# AM13E23219 register map
Vendor: Texas Instruments; File version: 1.0
CPU: CM33 r0p1, little endian, MPU, FPU, VTOR, 4 interrupt priority bits
Registers are 32-bit, read-write, reset 0x0 unless marked. A register's access mark holds for its fields unless they carry their own. Offsets are from the block's base; [hi:lo] are bit positions; {n}, {i} and the like mark numbered series; 'fields as' and 'values as' point back to an identical list; <NAME> marks a mode.

## SYSCTL (part 1 of 2) — SYSCTL module
Base 0x400AF000
0x1020 IIDX ro — SYSCTL interrupt index
  [2:0] STAT — The SYSCTL interrupt index (IIDX) register generates a value corresponding to the highest priority pending interrupt source. This value may be used as an address offset for fast, deterministic handling in the interrupt service routine. A read of the IIDX register will clear the corresponding interrupt status in the RIS and MIS registers.
    0=NO_INTR (No interrupt pending); 1=LFOSCGOOD (LFOSCGOOD interrupt pending); 2=ANACLKERR; 3=FLASHSEC; 4=SRAMSEC; 5=HFCLKGOOD; 6=SYSPLLGOOD; 7=HSCLKGOOD
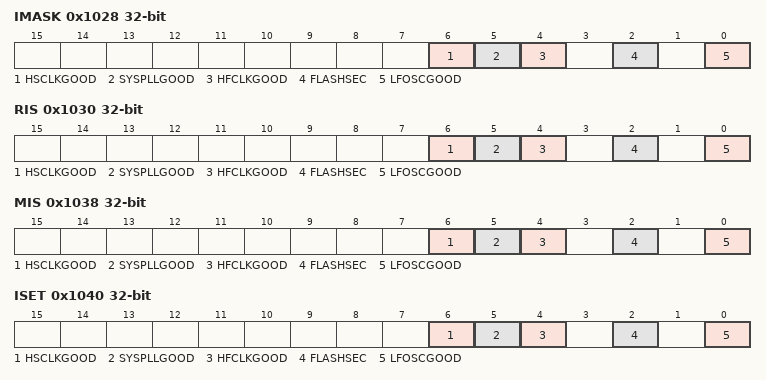
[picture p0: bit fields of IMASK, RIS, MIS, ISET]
0x1028 IMASK — SYSCTL interrupt mask
  [6] HSCLKGOOD
    0=DISABLE; 1=ENABLE
  [5] SYSPLLGOOD
    0=DISABLE; 1=ENABLE
  [4] HFCLKGOOD
    0=DISABLE; 1=ENABLE
  [2] FLASHSEC — Flash Single Error Correct
    0=DISABLE; 1=ENABLE
  [0] LFOSCGOOD — Enable or disable the LFOSCGOOD interrupt. LFOSCGOOD indicates that the LFOSC has started successfully.
    0=DISABLE (Interrupt disabled); 1=ENABLE (Interrupt enabled)
0x1030 RIS ro — SYSCTL raw interrupt status
  [6] HSCLKGOOD
    0=FALSE; 1=TRUE
  [5] SYSPLLGOOD
    0=FALSE; 1=TRUE
  [4] HFCLKGOOD
    0=FALSE; 1=TRUE
  [2] FLASHSEC — Flash Single Error Correct
    0=FALSE; 1=TRUE
  [0] LFOSCGOOD — Raw status of the LFOSCGOOD interrupt.
    0=FALSE (No interrupt pending); 1=TRUE (Interrupt pending)
0x1038 MIS ro — SYSCTL masked interrupt status
  [6] HSCLKGOOD
    0=FALSE; 1=TRUE
  [5] SYSPLLGOOD
    0=FALSE; 1=TRUE
  [4] HFCLKGOOD
    0=FALSE; 1=TRUE
  [2] FLASHSEC — Flash Single Error Correct
    0=FALSE; 1=TRUE
  [0] LFOSCGOOD — Masked status of the LFOSCGOOD interrupt.
    0=FALSE (No interrupt pending); 1=TRUE (Interrupt pending)
0x1040 ISET — SYSCTL interrupt set
  [6] HSCLKGOOD
    0=NO_EFFECT; 1=SET
  [5] SYSPLLGOOD
    0=NO_EFFECT; 1=SET
  [4] HFCLKGOOD
    0=NO_EFFECT; 1=SET
  [2] FLASHSEC — Flash Single Error Correct
    0=NO_EFFECT; 1=SET
  [0] LFOSCGOOD — Set the LFOSCGOOD interrupt.
    0=NO_EFFECT (Writing 0h has no effect); 1=SET (Set interrupt)
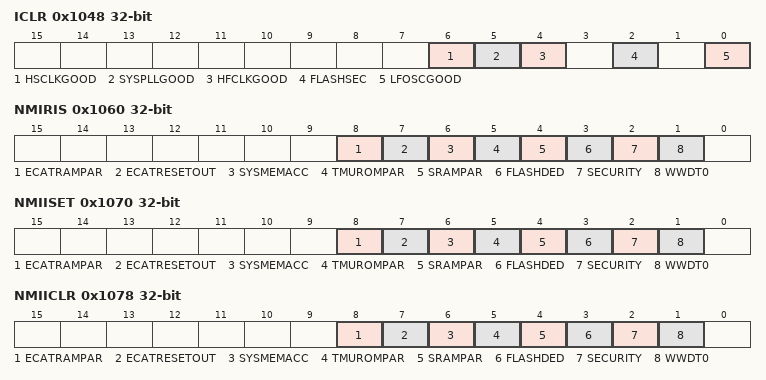
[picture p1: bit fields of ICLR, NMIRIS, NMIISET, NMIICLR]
0x1048 ICLR — SYSCTL interrupt clear
  [6] HSCLKGOOD
    0=NO_EFFECT; 1=CLR
  [5] SYSPLLGOOD
    0=NO_EFFECT; 1=CLR
  [4] HFCLKGOOD
    0=NO_EFFECT; 1=CLR
  [2] FLASHSEC — Flash Single Error Correct
    0=NO_EFFECT; 1=CLR
  [0] LFOSCGOOD — Clear the LFOSCGOOD interrupt.
    0=NO_EFFECT (Writing 0h has no effect); 1=CLR (Clear interrupt)
0x1050 NMIIIDX ro — NMI interrupt index
  [3:0] STAT — The NMI interrupt index (NMIIIDX) register generates a value corresponding to the highest priority pending NMI source. This value may be used as an address offset for fast, deterministic handling in the NMI service routine. A read of the NMIIIDX register will clear the corresponding interrupt status in the NMIRIS register.
    0=NO_INTR (No NMI pending); 1=BORLVL (Reserved); 2=WWDT0; 3=SECURITY; 4=FLASHDED; 5=SRAMPAR; 6=TMUROMPAR; 7=SYSMEMACC; 8=ECATRESETOUT; 9=ECATRAMPAR
0x1060 NMIRIS ro — NMI raw interrupt status
  [all] fields
    0=FALSE; 1=TRUE
  [8] ECATRAMPAR — ECATSS RAM Parity error
  [7] ECATRESETOUT — ECATSS RESET out
  [6] SYSMEMACC — SYSMEM Access error
  [5] TMUROMPAR — TMU ROM Parity error
  [4] SRAMPAR — SRAM Parity Error Detect
  [3] FLASHDED — Flash Double Error Detect
  [2] SECURITY — Security Fault
  [1] WWDT0 — Watch Dog 0 Fault
0x1070 NMIISET — NMI interrupt set
  [all] fields
    0=NO_EFFECT; 1=SET
  [8] ECATRAMPAR — ECATSS RAM Parity error
  [7] ECATRESETOUT — ECATSS RESET out
  [6] SYSMEMACC — SYSMEM Access error
  [5] TMUROMPAR — TMU ROM Parity error
  [4] SRAMPAR — SRAM Parity Error Detect
  [3] FLASHDED — Flash Double Error Detect
  [2] SECURITY — Security Fault
  [1] WWDT0 — Watch Dog 0 Fault
0x1078 NMIICLR — NMI interrupt clear
  [all] fields
    0=NO_EFFECT; 1=CLR
  [8] ECATRAMPAR — ECATSS RAM Parity error
  [7] ECATRESETOUT — ECATSS RESET out
  [6] SYSMEMACC — SYSMEM Access error
  [5] TMUROMPAR — TMU ROM Parity error
  [4] SRAMPAR — SRAM Parity Error Detect
  [3] FLASHDED — Flash Double Error Detect
  [2] SECURITY — Security Fault
  [1] WWDT0 — Watch Dog 0 Fault
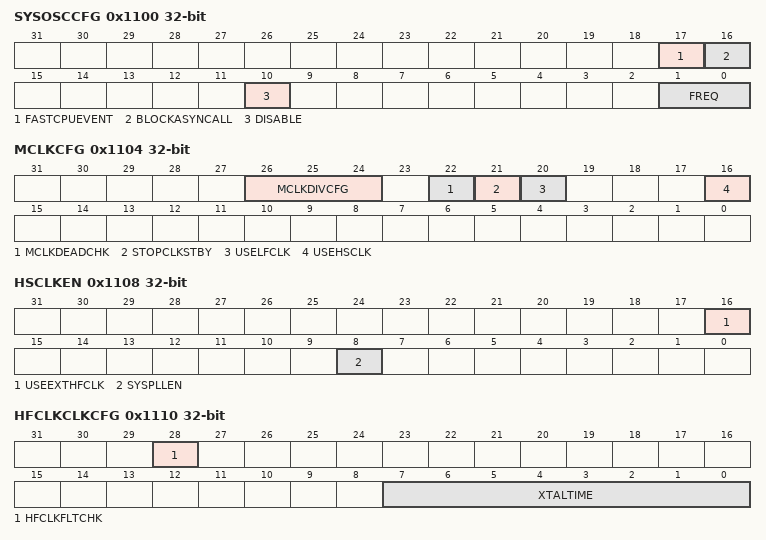
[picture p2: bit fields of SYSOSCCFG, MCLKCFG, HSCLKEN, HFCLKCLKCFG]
0x1100 SYSOSCCFG access per field — SYSOSC configuration
  [17] FASTCPUEVENT rw — if disabled CPU will not wakeup and continue in STANDBY
    0=DISABLE (An interrupt to the CPU will not assert a fast clock request); 1=ENABLE (An interrupt to the CPU will assert a fast clock request)
  [16] BLOCKASYNCALL rw — BLOCKASYNCALL may be used to mask block all asynchronous fast clock requests, preventing hardware from dynamically changing the active clock configuration when operating in a given mode.
    0=DISABLE (Asynchronous fast clock requests are controlled by the requesting peripheral); 1=ENABLE (All asynchronous fast clock requests are blocked)
  [10] DISABLE ro — DISABLE sets the SYSOSC enable/disable policy. SYSOSC may be powered off in RUN, SLEEP, and STOP modes to reduce power consumption. When SYSOSC is disabled, MCLK and ULPCLK are sourced from LFCLK.
    0=DISABLE (Do not disable SYSOSC); 1=ENABLE (Disable SYSOSC immediately and source MCLK and ULPCLK from LFCLK)
  [1:0] FREQ rw — Target operating frequency for the system oscillator (SYSOSC)
    0=SYSOSCBASE (Base frequency (32MHz)); 1=SYSOSC4M (Low frequency (4MHz))
0x1104 MCLKCFG access per field — Main clock (MCLK) configuration
  [26:24] MCLKDIVCFG rw — MCLK Divider Configuration bits [1:0] are defined as MCLK4 is Bypass, MCLK2 is Bypass
    0=RATIO_1_1_1 (MCLK: No Divide, MCLK2: No Divide, MCLK4: No Divide); 1=RATIO_1_1_2 (MCLK: No Divide, MCLK2: No Divide, MCLK4: Divide MCLK by 2); 3=RATIO_1_1_4 (MCLK: No Divide, MCLK2: No Divide, MCLK4: Divide MCLK by 4); 5=RATIO_1_2_2 (MCLK: No Divide, MCLK2: Divide MCLK by 2, MCLK4: Divide MCLK by 2); 7=RATIO_1_2_4 (MCLK: No Divide, MCLK2: Divide MCLK by 2, MCLK4: MCLK by 4)
  [22] MCLKDEADCHK rw — MCLKDEADCHK enables or disables the continuous MCLK dead check monitor. LFCLK must be running before MCLKDEADCHK is enabled.
    0=DISABLE (The MCLK dead check monitor is disabled); 1=ENABLE (The MCLK dead check monitor is enabled)
  [21] STOPCLKSTBY rw — STOPCLKSTBY sets the STANDBY mode policy (STANDBY0 or STANDBY1). When set, ULPCLK and LFCLK are disabled to all peripherals in STANDBY mode, with the exception of TIMG0 and TIMG1 which continue to run. Wake-up is only possible via an asynchronous fast clock request.
    0=DISABLE (ULPCLK/LFCLK runs to all PD0 peripherals in STANDBY mode); 1=ENABLE (ULPCLK/LFCLK is disabled to all peripherals in STANDBY mode except TIMG0 and TIMG1)
  [20] USELFCLK ro — LFCLK is not an MCLK sourcei in PD1, tied 0.
    0=DISABLE (MCLK will not use the low frequency clock (LFCLK)); 1=ENABLE (MCLK will use the low frequency clock (LFCLK))
  [16] USEHSCLK rw — USEHSCLK, together with USELFCLK, sets the MCLK source policy. Set USEHSCLK to use HSCLK (HFCLK or SYSPLL) as the MCLK source in RUN and SLEEP modes.
    0=DISABLE (MCLK will not use the high speed clock (HSCLK)); 1=ENABLE (MCLK will use the high speed clock (HSCLK) in RUN and SLEEP mode)
0x1108 HSCLKEN — High-speed clock (HSCLK) source enable/disable
  [16] USEEXTHFCLK — USEEXTHFCLK selects the HFCLK_IN digital clock input to be the source for HFCLK.
    0=DISABLE (Use XTAL as the HFCLK source); 1=ENABLE (Use the HFCLK_IN digital clock input as the HFCLK source)
  [8] SYSPLLEN — SYSPLLEN enables or disables the system phase-lock loop (SYSPLL).
    0=DISABLE (Disable the SYSPLL); 1=ENABLE (Enable the SYSPLL)
0x110C HSCLKCFG — High-speed clock (HSCLK) source selection
  [0] HSCLKSEL — HSCLKSEL selects the HSCLK source (SYSPLL or HFCLK).
    0=SYSPLL (HSCLK is sourced from the SYSPLL); 1=HFCLKCLK (HSCLK is sourced from the HFCLK)
0x1110 HFCLKCLKCFG — High-frequency clock (HFCLK) configuration
  [28] HFCLKFLTCHK — HFCLKFLTCHK enables or disables the HFCLK startup monitor.
    0=DISABLE (HFCLK startup is not checked); 1=ENABLE (HFCLK startup is checked)
  [7:0] XTALTIME — XTALTIME specifies the XTAL startup time in 64us resolution. If the HFCLK startup monitor is enabled (HFCLKFLTCHK), XTAL will be checked after this time expires.
    0=MINSTARTTIME (Minimum startup time (approximatly zero)); 255=MAXSTARTTIME (Maximum startup time (approximatly 16.32ms))
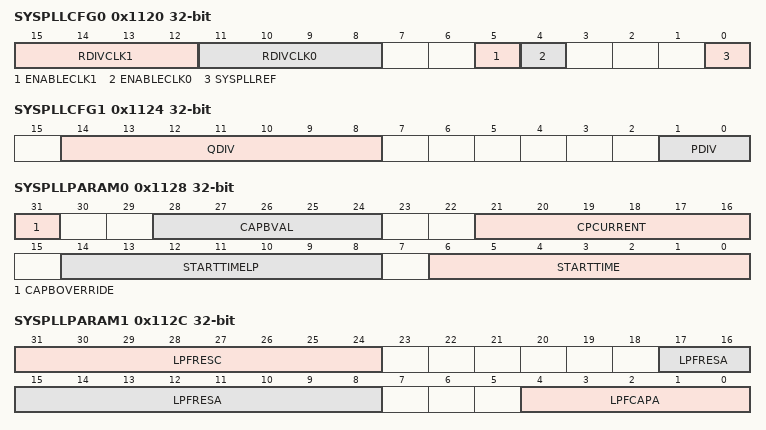
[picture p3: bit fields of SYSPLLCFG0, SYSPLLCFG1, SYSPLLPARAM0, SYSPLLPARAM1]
0x1120 SYSPLLCFG0 — SYSPLL reference and output configuration
  [15:12] RDIVCLK1 — RDIVCLK1 sets the final divider for the SYSPLLCLK1 output.
    0=CLK1DIV2 (SYSPLLCLK1 is divided by 2); 1=CLK1DIV4 (SYSPLLCLK1 is divided by 4); 2=CLK1DIV6 (SYSPLLCLK1 is divided by 6); 3=CLK1DIV8 (SYSPLLCLK1 is divided by 8); 4=CLK1DIV10 (SYSPLLCLK1 is divided by 10); 5=CLK1DIV12 (SYSPLLCLK1 is divided by 12); 6=CLK1DIV14 (SYSPLLCLK1 is divided by 14); 7=CLK1DIV16 (SYSPLLCLK1 is divided by 16); 8=CLK1DIV18 (SYSPLLCLK1 is divided by 18); 9=CLK1DIV20 (SYSPLLCLK1 is divided by 20); 10=CLK1DIV22 (SYSPLLCLK1 is divided by 22); 11=CLK1DIV24 (SYSPLLCLK1 is divided by 24); 12=CLK1DIV26 (SYSPLLCLK1 is divided by 26); 13=CLK1DIV28 (SYSPLLCLK1 is divided by 28); 14=CLK1DIV30 (SYSPLLCLK1 is divided by 30); 15=CLK1DIV32 (SYSPLLCLK1 is divided by 32)
  [11:8] RDIVCLK0 — RDIVCLK0 sets the final divider for the SYSPLLCLK0 output.
    0=CLK0DIV2 (SYSPLLCLK0 is divided by 2); 1=CLK0DIV4 (SYSPLLCLK0 is divided by 4); 2=CLK0DIV6 (SYSPLLCLK0 is divided by 6); 3=CLK0DIV8 (SYSPLLCLK0 is divided by 8); 4=CLK0DIV10 (SYSPLLCLK0 is divided by 10); 5=CLK0DIV12 (SYSPLLCLK0 is divided by 12); 6=CLK0DIV14 (SYSPLLCLK0 is divided by 14); 7=CLK0DIV16 (SYSPLLCLK0 is divided by 16); 8=CLK0DIV18 (SYSPLLCLK0 is divided by 18); 9=CLK0DIV20 (SYSPLLCLK0 is divided by 20); 10=CLK0DIV22 (SYSPLLCLK0 is divided by 22); 11=CLK0DIV24 (SYSPLLCLK0 is divided by 24); 12=CLK0DIV26 (SYSPLLCLK0 is divided by 26); 13=CLK0DIV28 (SYSPLLCLK0 is divided by 28); 14=CLK0DIV30 (SYSPLLCLK0 is divided by 30); 15=CLK0DIV32 (SYSPLLCLK0 is divided by 32)
  [5] ENABLECLK1 — ENABLECLK1 enables or disables the SYSPLLCLK1 output.
    0=DISABLE (SYSPLLCLK1 is disabled); 1=ENABLE (SYSPLLCLK1 is enabled)
  [4] ENABLECLK0 — ENABLECLK0 enables or disables the SYSPLLCLK0 output.
    0=DISABLE (SYSPLLCLK0 is disabled); 1=ENABLE (SYSPLLCLK0 is enabled)
  [0] SYSPLLREF — SYSPLLREF selects the system PLL (SYSPLL) reference clock source.
    0=SYSOSC (SYSPLL reference is SYSOSC); 1=HFCLK (SYSPLL reference is HFCLK)
0x1124 SYSPLLCFG1 — SYSPLL reference and feedback divider
  [14:8] QDIV — QDIV selects the SYSPLL feedback path divider.
    0=INVALID (Divide-by-one is not a valid QDIV option); 1=QDIVMIN (Feedback path is divided by 2); 126=QDIVMAX (Feedback path is divided by 127 (0x7E))
  [1:0] PDIV — PDIV selects the SYSPLL reference clock prescale divider.
    0=REFDIV1 (SYSPLLREF is not divided); 1=REFDIV2 (SYSPLLREF is divided by 2); 2=REFDIV4 (SYSPLLREF is divided by 4); 3=REFDIV8 (SYSPLLREF is divided by 8)
0x1128 SYSPLLPARAM0 — SYSPLL PARAM0 (load from FACTORY region)
  [31] CAPBOVERRIDE — CAPBOVERRIDE controls the override for Cap B
    0=DISABLE (Cap B override disabled); 1=ENABLE (Cap B override enabled)
  [28:24] CAPBVAL — Override value for Cap B
  [21:16] CPCURRENT — Charge pump current
  [14:8] STARTTIMELP — Startup time from low power mode exit to locked clock, in 1us resolution
  [6:0] STARTTIME — Startup time from enable to locked clock, in 1us resolution
0x112C SYSPLLPARAM1 — SYSPLL PARAM1 (load from FACTORY region)
  [31:24] LPFRESC — Loop filter Res C
  [17:8] LPFRESA — Loop filter Res A
  [4:0] LPFCAPA — Loop filter Cap A
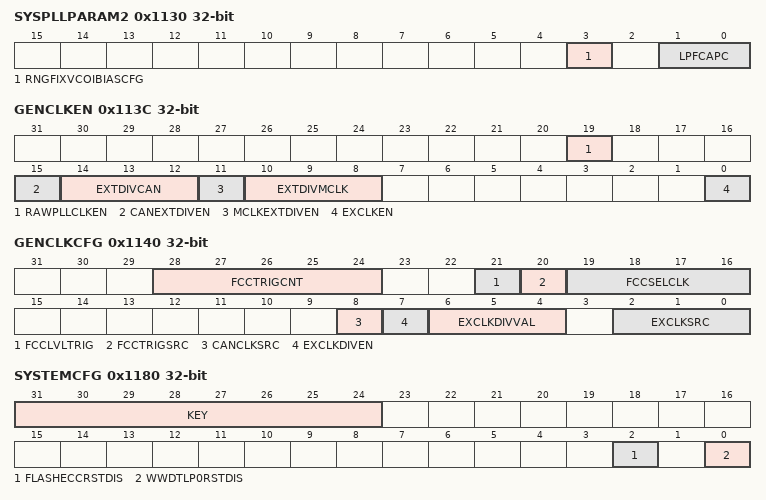
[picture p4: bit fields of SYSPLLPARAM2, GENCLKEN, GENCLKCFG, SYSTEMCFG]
0x1130 SYSPLLPARAM2 — SYSPLL PARAM2 (load from FACTORY region)
  [3] RNGFIXVCOIBIASCFG — 0 value for Temperature Compensation R addition
  [1:0] LPFCAPC — Loop filter Cap C
0x1134 SYSPLLLDOCTL — SYSPLL LDO CTL (load from FACTORY region)
  [15:0] LDOCTLLOWV — LDO Configurability
0x1138 SYSPLLLDOPROG — SYSPLL LDO VOUT PROG (load from FACTORY region)
  [2:0] LDOVOUTPROGLOWV — HPLL LDO Vout Prog
0x113C GENCLKEN — General clock enable control
  [19] RAWPLLCLKEN — RAWPLLCLKEN enables or disables the 400MHz RAW PLL clock into the system
    0=DISBLE (400MHz RAW PLL clock is disabled); 1=ENABLE (400MHz RAW PLL clock is enabled)
  [15] CANEXTDIVEN — CANEXTDIVEN enables or disables the divider function of the PLL Source to CAN.
    0=PASSTHRU (CLock divider is disabled (passthrough, EXTDIVCAN is not applied)); 1=ENABLE (Clock divider is enabled (EXTDIVCAN is applied))
  [14:12] EXTDIVCAN — EXTDIVCAN selects the divider value for the divider for the PLL Source to CAN.
    0=DIV2 (CLK_OUT source is divided by 2); 1=DIV4 (CLK_OUT source is divided by 4); 2=DIV6 (CLK_OUT source is divided by 6); 3=DIV8 (CLK_OUT source is divided by 8); 4=DIV10 (CLK_OUT source is divided by 10); 5=DIV12 (CLK_OUT source is divided by 12); 6=DIV14 (CLK_OUT source is divided by 14); 7=DIV16 (CLK_OUT source is divided by 16)
  [11] MCLKEXTDIVEN — MCLKEXTDIVEN enables or disables the divider function of the PLL Source to MCLK.
    0=PASSTHRU (CLock divider is disabled (passthrough, EXTDIVMCLK is not applied)); 1=ENABLE (Clock divider is enabled (EXTDIVMCLK is applied))
  [10:8] EXTDIVMCLK — EXTDIVMCLK selects the divider value for the divider for the PLL Source MCLK.
    values as EXTDIVCAN
  [0] EXCLKEN — EXCLKEN enables the CLK_OUT external clock output block.
    0=DISABLE (CLK_OUT block is disabled); 1=ENABLE (CLK_OUT block is enabled)
0x1140 GENCLKCFG — General clock configuration
  [28:24] FCCTRIGCNT — FCCTRIGCNT specifies the number of trigger clock periods in the trigger window. FCCTRIGCNT=0h (one trigger clock period) up to 1Fh (32 trigger clock periods) may be specified.
  [21] FCCLVLTRIG — FCCLVLTRIG selects the frequency clock counter (FCC) trigger mode.
    0=RISE2RISE (Rising edge to rising edge triggered); 1=LEVEL (Level triggered)
  [20] FCCTRIGSRC — FCCTRIGSRC selects the frequency clock counter (FCC) trigger source.
    0=EXTPIN (FCC trigger is the external pin); 1=LFCLK (FCC trigger is the LFCLK)
  [19:16] FCCSELCLK — FCCSELCLK selectes the frequency clock counter (FCC) clock source.
    0=MCLKBY4 (FCC clock is MCLK/4); 1=SYSOSC (FCC clock is SYSOSC); 2=HFCLK (FCC clock is HFCLK); 3=EXTCLK (FCC clock is the CLK_OUT selection); 4=SYSPLLCLK0 (FCC clock is SYSPLLCLK0); 5=SYSPLLCLK1 (FCC clock is SYSPLLCLK1); 6=ECAT25CLK (FCC clock is ECAT25CLK); 7=FCCIN (FCC clock is the FCCIN external input)
  [8] CANCLKSRC — CANCLKSRC selects the CANCLK source.
    0=HFCLK (CANCLK source is HFCLK); 1=SYSPLLOUT (CANCLK source is SYSPLLCLK)
  [7] EXCLKDIVEN — EXCLKDIVEN enables or disables the divider function of the CLK_OUT external clock output block.
    0=PASSTHRU (CLock divider is disabled (passthrough, EXCLKDIVVAL is not applied)); 1=ENABLE (Clock divider is enabled (EXCLKDIVVAL is applied))
  [6:4] EXCLKDIVVAL — EXCLKDIVVAL selects the divider value for the divider in the CLK_OUT external clock output block.
    values as GENCLKEN.EXTDIVCAN
  [2:0] EXCLKSRC — EXCLKSRC selects the source for the CLK_OUT external clock output block. ULPCLK and MFPCLK require the CLK_OUT divider (EXCLKDIVEN) to be enabled
    0=SYSOSC (CLK_OUT is SYSOSC); 1=ULPCLK (CLK_OUT is ULPCLK (EXCLKDIVEN must be enabled)); 2=LFCLK (CLK_OUT is LFCLK); 3=MFPCLK (CLK_OUT is MFPCLK (EXCLKDIVEN must be enabled)); 4=HFCLK (CLK_OUT is HFCLK); 5=SYSPLLOUT1 (CLK_OUT is SYSPLLCLK1 (SYSPLLCLK1 must be <=48MHz))
0x1144 PMODECFG — Power mode configuration
  [1:0] DSLEEP — DSLEEP selects the operating mode to enter upon a DEEPSLEEP request from the CPU.
    0=STOP (STOP mode is entered); 1=STANDBY (STANDBY mode is entered); 2=SHUTDOWN (SHUTDOWN mode is entered)
0x1148 MLDOLPENCFG — LDO Configuration Control
  [0] CVLODIS — Control to disable lowering the core voltage for STOP and STANDBY
    0=FALSE (Lower Core Voltage for STOP and STANDBY mode); 1=TRUE (Do Not Lower Core Voltage for STOP and STANDBY mode to provide faster wakeup)
0x1150 FCC ro — Frequency clock counter (FCC) count
  [21:0] DATA — Frequency clock counter (FCC) count value.
0x1154 PMULDOSPARECTL access not given — LDO Spare Control
0x1158 SYSCTL_ECO_REG1 access not given
0x115C SYSCTL_ECO_REG2 access not given
0x1180 SYSTEMCFG access per field — System configuration
  [31:24] KEY wo — Key which must be written for the write to take effect.
    27=KEY (Write key.)
  [2] FLASHECCRSTDIS rw — FLASHECCRSTDIS specifies whether a flash ECC double error detect (DED) will trigger a SYSRST or an NMI.
    0=FALSE (Flash ECC DED will trigger a SYSRST); 1=TRUE (Flash ECC DED will trigger a NMI)
  [0] WWDTLP0RSTDIS rw — WWDTLP0RSTDIS specifies whether a WWDT Error Event will trigger a BOOTRST or an NMI.
    0=FALSE (WWDTLP0 Error Event will trigger a BOOTRST); 1=TRUE (WWDTLP0 Error Event will trigger an NMI)
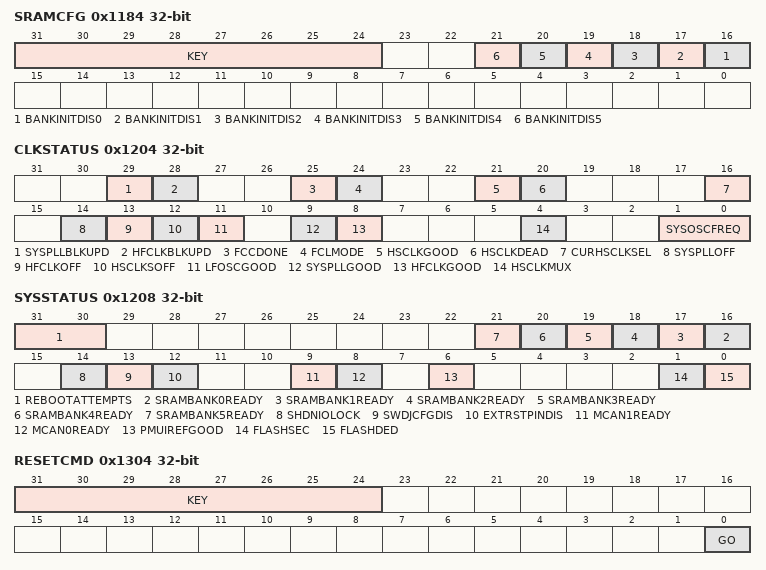
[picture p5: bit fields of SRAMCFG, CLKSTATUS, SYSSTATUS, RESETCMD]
0x1184 SRAMCFG access per field — System SRAM configuration
  [31:24] KEY wo — Key which must be written for the write to take effect.
    181=KEY (Write key.)
  [n+16] BANKINITDIS{n} rw (n=0..5) — SRAM BANK{n} Initialization
    0=FALSE (SRAM BANK{n} will Initialize when transitioning from OFF to ON); 1=TRUE (SRAM BANK{n} will NOT Initialize when transitioning from OFF to ON)
0x1200 WRITELOCK — SYSCTL register write lockout
  [0] ACTIVE — ACTIVE controls whether critical SYSCTL registers are write protected or not.
    0=DISABLE (Allow writes to lockable registers); 1=ENABLE (Disallow writes to lockable registers)
0x1204 CLKSTATUS ro — Clock module (CKM) status
  [29] SYSPLLBLKUPD — SYSPLLBLKUPD indicates when writes to SYSPLLCFG0/1 and SYSPLLPARAM0/1 are blocked.
    0=FALSE (writes to SYSPLLCFG0/1 and SYSPLLPARAM0/1 are allowed); 1=TRUE (writes to SYSPLLCFG0/1 and SYSPLLPARAM0/1 are blocked)
  [28] HFCLKBLKUPD — HFCLKBLKUPD indicates when writes to the HFCLKCLKCFG register are blocked.
    0=FALSE (Writes to HFCLKCLKCFG are allowed); 1=TRUE (Writes to HFCLKCLKCFG are blocked)
  [25] FCCDONE — FCCDONE indicates when a frequency clock counter capture is complete.
    0=NOTDONE (FCC capture is not done); 1=DONE (FCC capture is done)
  [24] FCLMODE — FCLMODE indicates if the SYSOSC frequency correction loop (FCL) is enabled.
    0=DISABLED (SYSOSC FCL is disabled); 1=ENABLED (SYSOSC FCL is enabled)
  [21] HSCLKGOOD — HSCLKGOOD is set by hardware if the selected clock source for HSCLK started successfully.
    0=FALSE (The HSCLK source did not start correctly); 1=TRUE (The HSCLK source started correctly)
  [20] HSCLKDEAD — HSCLKDEAD is set by hardware if the selected source for HSCLK was started but did not start successfully.
    0=FALSE (The HSCLK source was not started or started correctly); 1=TRUE (The HSCLK source did not start correctly)
  [16] CURHSCLKSEL — CURHSCLKSEL indicates the current clock source for HSCLK.
    0=SYSPLL (HSCLK is currently sourced from the SYSPLL); 1=HFCLK (HSCLK is currently sourced from the HFCLK)
  [14] SYSPLLOFF — SYSPLLOFF indicates if the SYSPLL is disabled or was dead at startup. When the SYSPLL is started, SYSPLLOFF is cleared by hardware. Following startup of the SYSPLL, if the SYSPLL startup monitor determines that the SYSPLL was not started correctly, SYSPLLOFF is set.
    0=FALSE (SYSPLL started correctly and is enabled); 1=TRUE (SYSPLL is disabled or was dead startup)
  [13] HFCLKOFF — HFCLKOFF indicates if the HFCLK is disabled or was dead at startup. When the HFCLK is started, HFCLKOFF is cleared by hardware. Following startup of the HFCLK, if the HFCLK startup monitor determines that the HFCLK was not started correctly, HFCLKOFF is set.
    0=FALSE (HFCLK started correctly and is enabled); 1=TRUE (HFCLK is disabled or was dead at startup)
  [12] HSCLKSOFF — HSCLKSOFF is set when the high speed clock sources (SYSPLL, HFCLK) are disabled or dead. It is the logical AND of HFCLKOFF and SYSPLLOFF.
    0=FALSE (SYSPLL, HFCLK, or both were started correctly and remain enabled); 1=TRUE (SYSPLL and HFCLK are both either off or dead)
  [11] LFOSCGOOD — LFOSCGOOD indicates when the LFOSC startup has completed and the LFOSC is ready for use.
    0=FALSE (LFOSC is not ready); 1=TRUE (LFOSC is ready)
  [9] SYSPLLGOOD — SYSPLLGOOD indicates if the SYSPLL started correctly. When the SYSPLL is started, SYSPLLGOOD is cleared by hardware. After the startup settling time has expired, the SYSPLL status is tested. If the SYSPLL started successfully the SYSPLLGOOD bit is set, else it is left cleared.
    0=FALSE (SYSPLL did not start correctly); 1=TRUE (SYSPLL started correctly)
  [8] HFCLKGOOD — HFCLKGOOD indicates that the HFCLK started correctly. When the XTAL is started or HFCLK_IN is selected as the HFCLK source, this bit will be set by hardware if a valid HFCLK is detected, and cleared if HFCLK is not operating within the expected range.
    0=FALSE (HFCLK did not start correctly); 1=TRUE (HFCLK started correctly)
  [4] HSCLKMUX — HSCLKMUX indicates if MCLK is currently sourced from the high-speed clock (HSCLK).
    0=SYSOSC (MCLK is not sourced from HSCLK); 1=HSCLK (MCLK is sourced from HSCLK)
  [1:0] SYSOSCFREQ — SYSOSCFREQ indicates the current SYSOSC operating frequency.
    0=SYSOSC32M (SYSOSC is at base frequency (32MHz)); 1=SYSOSC4M (SYSOSC is at low frequency (4MHz))
0x1208 SYSSTATUS ro — System status information
  [31:30] REBOOTATTEMPTS — REBOOTATTEMPTS indicates the number of boot attempts taken before the user application starts.
  [n+16] SRAMBANK{n}READY (n=0..5) — SRAM BANK{n} READY STATE
    0=FALSE (SRAM BANK{n} is NOT READY for access); 1=TRUE (SRAM BANK{n} is READY for access)
  [14] SHDNIOLOCK — SHDNIOLOCK indicates when IO is locked due to SHUTDOWN
    0=FALSE (IO IS NOT Locked due to SHUTDOWN); 1=TRUE (IO IS Locked due to SHUTDOWN)
  [13] SWDJCFGDIS — SWDJCFGDIS indicates when user has disabled the use of SWD/JTAG Port
    0=FALSE (SWD/JTAG Port Enabled); 1=TRUE (SWD/JTAG Port Disabled)
  [12] EXTRSTPINDIS — EXTRSTPINDIS indicates when user has disabled the use of external reset pin
    0=FALSE (External Reset Pin Enabled); 1=TRUE (External Reset Pin Disabled)
  [9] MCAN1READY — MCAN1READY indicates when the MCAN1 peripheral is ready.
    0=FALSE (MCAN1 is not ready); 1=TRUE (MCAN1 is ready)
  [8] MCAN0READY — MCAN0READY indicates when the MCAN0 peripheral is ready.
    0=FALSE (MCAN0 is not ready); 1=TRUE (MCAN0 is ready)
  [6] PMUIREFGOOD — PMUIREFGOOD is set by hardware when the PMU current reference is ready.
    0=FALSE (IREF is not ready); 1=TRUE (IREF is ready)
  [1] FLASHSEC — FLASHSEC indicates if a flash ECC single bit error was detected and corrected (SEC).
    0=FALSE (No flash ECC single bit error detected); 1=TRUE (Flash ECC single bit error was detected and corrected)
  [0] FLASHDED — FLASHDED indicates if a flash ECC double bit error was detected (DED).
    0=FALSE (No flash ECC double bit error detected); 1=TRUE (Flash ECC double bit error detected)
0x1220 RSTCAUSE ro — Reset cause
  [4:0] ID — ID is a read-to-clear field which indicates the lowest level reset cause since the last read.
    0=NORST (No reset since last read); 1=PORHWFAIL (POR- violation, SHUTDNSTOREx or PMU trim parity fault); 2=POREXNRST (NRST triggered POR (>1s hold)); 3=PORSW (Software triggered POR); 4=BORSUPPLY (BOR0- violation); 5=BORWAKESHUTDN (SHUTDOWN mode exit); 8=BOOTNONPMUPARITY (Non-PMU trim parity fault); 9=BOOTCLKFAIL (Fatal clock failure); 12=BOOTEXNRST (NRST triggered BOOTRST (<1s hold)); 13=BOOTSW (Software triggered BOOTRST); 14=BOOTWWDT0 (WWDT0 violation); 16=SYSBSLEXIT (BSL exit); 17=SYSBSLENTRY (BSL entry); 20=SYSFLASHECC (Flash uncorrectable ECC error); 21=SYSCPULOCK (CPULOCK violation); 26=SYSDBG (Debug triggered SYSRST); 27=SYSSW (Software triggered SYSRST); 28=CPUDBG (Debug triggered CPURST); 29=CPUSW (Software triggered CPURST)
0x1300 RESETLEVEL — Reset level for application-triggered reset command
  [2:0] LEVEL — LEVEL is used to specify the type of reset to be issued when RESETCMD is set to generate a software triggered reset.
    0=SYS (Issue a SYSRST (CPU plus peripherals only)); 1=BOOT (Issue a BOOTRST (CPU, peripherals, and boot configuration routine)); 2=BOOTLOADERENTRY (Issue a SYSRST and enter the boot strap loader (BSL)); 3=POR (Issue a power-on reset (POR)); 4=BOOTLOADEREXIT (Issue a SYSRST and exit the boot strap loader (BSL))
0x1304 RESETCMD access per field — Execute an application-triggered reset command
  [31:24] KEY wo — Key which must be written for the write to take effect.
    228=KEY (Write key.)
  [0] GO rw — Execute the reset specified in RESETLEVEL.LEVEL. Must be written together with the KEY.
    1=TRUE (Issue reset)
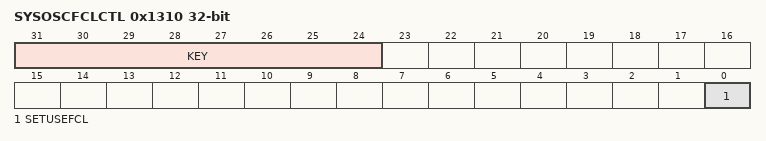
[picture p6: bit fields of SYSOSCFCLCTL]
0x1310 SYSOSCFCLCTL access per field — SYSOSC frequency correction loop (FCL) ROSC enable
  [31:24] KEY wo — Key which must be written for the write to take effect.
    42=KEY (Write key.)
  [0] SETUSEFCL rw — Set SETUSEFCL to enable the frequency correction loop in SYSOSC. Once enabled, this state is locked until the next BOOTRST.
    1=TRUE (Enable the SYSOSC FCL)
